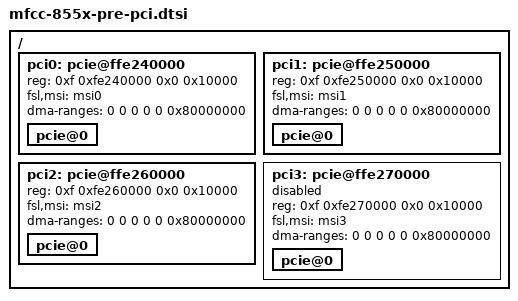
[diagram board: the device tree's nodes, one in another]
/*
 * Linux assumes all resources for a host have the same offset
 * to setup the PCSRBAR/PEXCSRBAR.
 *
 * In order to avoid any future issue, always define IO and MEM
 * resources with the same translation offset 
 * (CPU addr space <-> PCI addr space)
 */
/ {
	pci0: pcie@ffe240000 {
		reg = <0xf 0xfe240000 0x0 0x10000>;
		fsl,msi = <&msi0>;

		/* This device can only DMA address the bottom 2GB of RAM. */
		dma-ranges = <0 0 0 0 0 0x80000000>;

		ranges = <
			0x01000000		 /* PCI I/0 */
			0x00000000 0x00000000 	 /* PCI @ 0_0000_0000 */
			0x00000004 0x00000000 	 /* CPU @ 4_0000_0000 */
			0x00000000 0x00010000 	 /* Size 64 KB */

			0x02000000  	      	 /* PCI mem */
			0x00000000 0xc0000000 	 /* PCI @ 0_c000_0000h */
			0x00000004 0xc0000000 	 /* CPU @ 4_c000_0000h */
			0x00000000 0x40000000 	 /* Size 1GB */

			0x43000000   	      	 /* PCI mem prefetchable */
			0x00000001 0x00000000  	 /* PCI @ 1_0000_0000h */
			0x00000005 0x00000000  	 /* CPU @ 5_0000_0000h */
			0x00000001 0x00000000 	 /* Size 4GB */
		>;

		pcie@0 {
			ranges = <
				0x01000000 0x00000000 0x00000000
				0x01000000 0x00000000 0x00000000
				0x00000000 0x00010000

				0x02000000 0x00000000 0xc0000000
				0x02000000 0x00000000 0xc0000000
				0x00000000 0x40000000

				0x43000000 0x00000001 0x00000000
				0x43000000 0x00000001 0x00000000
				0x00000001 0x00000000
			>;
		};

	};

	pci1: pcie@ffe250000 {
		reg = <0xf 0xfe250000 0x0 0x10000>;
		fsl,msi = <&msi1>;

		/* This device can only DMA address the bottom 2GB of RAM. */
		dma-ranges = <0 0 0 0 0 0x80000000>;

		ranges = <
			0x01000000		 /* PCI I/0 */
			0x00000000 0x00000000 	 /* PCI @ 0_0000_0000 */
			0x00000007 0x00000000 	 /* CPU @ 7_0000_0000 */
			0x00000000 0x00010000 	 /* Size 64 KB */

			0x02000000  	      	 /* PCI mem */
			0x00000000 0xc0000000 	 /* PCI @ 0_c000_0000h */
			0x00000007 0xc0000000 	 /* CPU @ 7_c000_0000h */
			0x00000000 0x40000000 	 /* Size 1GB */

			0x43000000   	      	 /* PCI mem prefetchable */
			0x00000001 0x00000000  	 /* PCI @ 1_0000_0000h */
			0x00000008 0x00000000  	 /* CPU @ 8_0000_0000h */
			0x00000001 0x00000000 	 /* Size 4GB */
		>;

		pcie@0 {
			ranges = <
				0x01000000 0x00000000 0x00000000
				0x01000000 0x00000000 0x00000000
				0x00000000 0x00010000

				0x02000000 0x00000000 0xc0000000
				0x02000000 0x00000000 0xc0000000
				0x00000000 0x40000000

				0x43000000 0x00000001 0x00000000
				0x43000000 0x00000001 0x00000000
				0x00000001 0x00000000
			>;
		};
	};

	pci2: pcie@ffe260000 {
		reg = <0xf 0xfe260000 0x0 0x10000>;
		fsl,msi = <&msi2>;

		/* This device can only DMA address the bottom 2GB of RAM. */
		dma-ranges = <0 0 0 0 0 0x80000000>;

		ranges = <
			0x01000000		 /* PCI I/0 */
			0x00000000 0x00000000 	 /* PCI @ 0_0000_0000 */
			0x0000000a 0x00000000 	 /* CPU @ a_0000_0000 */
			0x00000000 0x00010000 	 /* Size 64 KB */

			0x02000000  	      	 /* PCI mem */
			0x00000000 0xc0000000 	 /* PCI @ 0_c000_0000h */
			0x0000000a 0xc0000000 	 /* CPU @ a_c000_0000h */
			0x00000000 0x40000000 	 /* Size 1GB */

			0x43000000   	      	 /* PCI mem prefetchable */
			0x00000001 0x00000000  	 /* PCI @ 1_0000_0000h */
			0x0000000b 0x00000000  	 /* CPU @ b_0000_0000h */
			0x00000001 0x00000000 	 /* Size 4GB */
		>;

		pcie@0 {
			ranges = <
				0x01000000 0x00000000 0x00000000
				0x01000000 0x00000000 0x00000000
				0x00000000 0x00010000

				0x02000000 0x00000000 0xc0000000
				0x02000000 0x00000000 0xc0000000
				0x00000000 0x40000000

				0x43000000 0x00000001 0x00000000
				0x43000000 0x00000001 0x00000000
				0x00000001 0x00000000
			>;
		};
	};

	pci3: pcie@ffe270000 {
		/* THJ TODO: setup as endpoint */
		status = "disabled";

		reg = <0xf 0xfe270000 0x0 0x10000>;
		fsl,msi = <&msi3>;

		/* This device can only DMA address the bottom 2GB of RAM. */
		dma-ranges = <0 0 0 0 0 0x80000000>;

		ranges = <
			0x01000000		 /* PCI I/0 */
			0x00000000 0x00000000 	 /* PCI @ 0_0000_0000 */
			0x0000000d 0x00000000 	 /* CPU @ d_0000_0000 */
			0x00000000 0x00010000 	 /* Size 64 KB */

			0x02000000  	      	 /* PCI mem */
			0x00000000 0x80000000 	 /* PCI @ 0_8000_0000h */
			0x0000000d 0x80000000 	 /* CPU @ d_8000_0000h */
			0x00000000 0x80000000 	 /* Size 2GB */

			0x43000000   	      	 /* PCI mem prefetchable */
			0x00000001 0x00000000  	 /* PCI @ 1_0000_0000h */
			0x0000000e 0x00000000  	 /* CPU @ e_0000_0000h */
			0x00000002 0x00000000 	 /* Size 8GB */
		>;

		pcie@0 {
			ranges = <
				0x01000000 0x00000000 0x00000000
				0x01000000 0x00000000 0x00000000
				0x00000000 0x00010000

				0x02000000 0x00000000 0x80000000
				0x02000000 0x00000000 0x80000000
				0x00000000 0x80000000

				0x43000000 0x00000001 0x00000000
				0x43000000 0x00000001 0x00000000
				0x00000002 0x00000000
			>;
		};
	};
};
